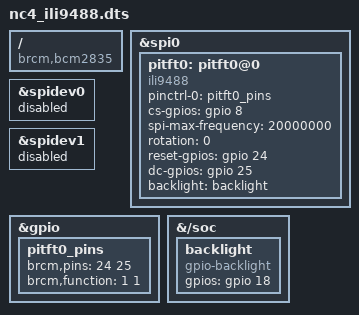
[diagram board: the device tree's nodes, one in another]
/dts-v1/;
/plugin/;

/ {
	compatible = "brcm,bcm2835";

	/****************************************************************************
	 * Fragment 0: Enable SPI0 hardware
	 ****************************************************************************/
	fragment@0 {
		target = <&spi0>;
		__overlay__ {
			status = "okay";
			
			/* If you like, you can declare "cs-gpios = <&gpio 8 0>, <&gpio 7 0>;"
			 * here, but typically you specify them in the child nodes below.
			 */
		};
	};

	/****************************************************************************
	 * Fragment 1: Disable spidev0
	 ****************************************************************************/
	fragment@1 {
		target = <&spidev0>;
		__overlay__ {
			status = "disabled";
		};
	};

	/****************************************************************************
	 * Fragment 2: Disable spidev1
	 ****************************************************************************/
	fragment@2 {
		target = <&spidev1>;
		__overlay__ {
			status = "disabled";
		};
	};

	/****************************************************************************
	 * Fragment 3: GPIO pins for the FIRST panel (pitft0)
	 *   GPIO24 = RESET (out)
	 *   GPIO25 = DC (out)
	 ****************************************************************************/
	fragment@3 {
		target = <&gpio>;
		__overlay__ {
			pitft0_pins: pitft0_pins {
				brcm,pins = <24 25>;
				brcm,function = <1 1>; /* Set as output */
			};
		};
	};

	/****************************************************************************
	 * Fragment 4: GPIO pins for the SECOND panel (pitft1)
	 *   GPIO23 = RESET (out)
	 *   GPIO27 = DC (out)
	 ****************************************************************************/
	// fragment@4 {
	// 	target = <&gpio>;
	// 	__overlay__ {
	// 		pitft1_pins: pitft1_pins {
	// 			brcm,pins = <23 27>;
	// 			brcm,function = <1 1>; /* Set as output */
	// 		};
	// 	};
	// };

	/****************************************************************************
	 * Fragment 5: FIRST ILI9488 device node on SPI0 
	 ****************************************************************************/
	fragment@5 {
		target = <&spi0>;
		__overlay__ {
			#address-cells = <1>;
			#size-cells = <0>;

			pitft0: pitft0@0 {
				compatible = "ili9488";
				pinctrl-names = "default";
				pinctrl-0 = <&pitft0_pins>;

				/* Use software CS on GPIO8 (active low). */
				cs-gpios = <&gpio 8 0>;
				spi-max-frequency = <20000000>;

				rotation = <0>;
				reset-gpios = <&gpio 24 0>;
				dc-gpios    = <&gpio 25 0>;
				backlight   = <&backlight>;
			};
		};
	};

	/****************************************************************************
	 * Fragment 6: SECOND ILI9488 device node on SPI0 
	 ****************************************************************************/
	// fragment@6 {
	// 	target = <&spi0>;
	// 	__overlay__ {
	// 		pitft1: pitft1@1 {
	// 			compatible = "ili9488";
	// 			pinctrl-names = "default";
	// 			pinctrl-0 = <&pitft1_pins>;

	// 			/* Use software CS on GPIO7 (active low). */
	// 			cs-gpios = <&gpio 7 0>;
	// 			spi-max-frequency = <20000000>;

	// 			rotation = <0>;
	// 			reset-gpios = <&gpio 23 0>;
	// 			dc-gpios = <&gpio 27 0>;
	// 			backlight = <&backlight>;
	// 		};
	// 	};
	// };

	/****************************************************************************
	 * Fragment 7: Shared backlight control for both panels
	 *   GPIO18 = Backlight (out)
	 ****************************************************************************/
	fragment@7 {
		target-path = "/soc";
		__overlay__ {
			backlight: backlight {
				compatible = "gpio-backlight";
				gpios = <&gpio 18 0>;
			};
		};
	};

	/****************************************************************************
	 * Overridable parameters for speed and rotation
	 ****************************************************************************/
	__overrides__ {
		speed = <&pitft0>,"spi-max-frequency:0", <&pitft1>,"spi-max-frequency:0";
		rotation = <&pitft0>,"rotation:0", <&pitft1>,"rotation:0";
	};
};
